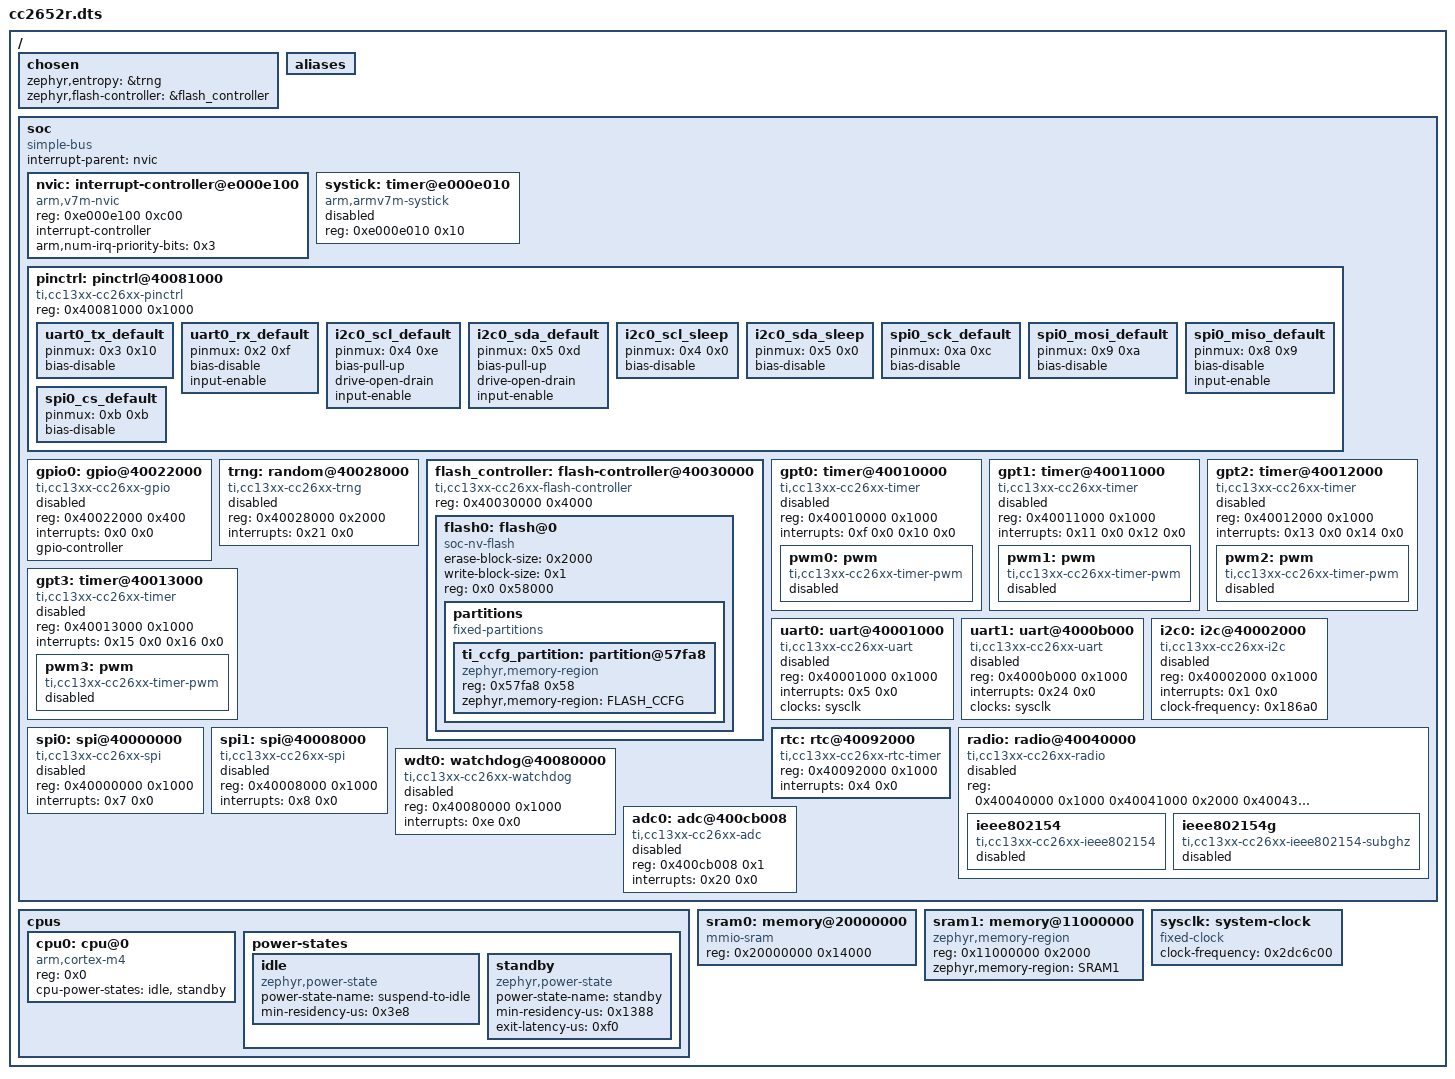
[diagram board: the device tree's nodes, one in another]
/dts-v1/;

/ {
	#address-cells = < 0x1 >;
	#size-cells = < 0x1 >;
	chosen {
		zephyr,entropy = &trng;
		zephyr,flash-controller = &flash_controller;
	};
	aliases {
	};
	soc {
		#address-cells = < 0x1 >;
		#size-cells = < 0x1 >;
		compatible = "simple-bus";
		interrupt-parent = < &nvic >;
		ranges;
		nvic: interrupt-controller@e000e100 {
			#address-cells = < 0x1 >;
			compatible = "arm,v7m-nvic";
			reg = < 0xe000e100 0xc00 >;
			interrupt-controller;
			#interrupt-cells = < 0x2 >;
			arm,num-irq-priority-bits = < 0x3 >;
			phandle = < 0x1 >;
		};
		systick: timer@e000e010 {
			compatible = "arm,armv7m-systick";
			reg = < 0xe000e010 0x10 >;
			status = "disabled";
		};
		pinctrl: pinctrl@40081000 {
			compatible = "ti,cc13xx-cc26xx-pinctrl";
			reg = < 0x40081000 0x1000 >;
			uart0_tx_default: uart0_tx_default {
				pinmux = < 0x3 0x10 >;
				bias-disable;
			};
			uart0_rx_default: uart0_rx_default {
				pinmux = < 0x2 0xf >;
				bias-disable;
				input-enable;
			};
			i2c0_scl_default: i2c0_scl_default {
				pinmux = < 0x4 0xe >;
				bias-pull-up;
				drive-open-drain;
				input-enable;
			};
			i2c0_sda_default: i2c0_sda_default {
				pinmux = < 0x5 0xd >;
				bias-pull-up;
				drive-open-drain;
				input-enable;
			};
			i2c0_scl_sleep: i2c0_scl_sleep {
				pinmux = < 0x4 0x0 >;
				bias-disable;
			};
			i2c0_sda_sleep: i2c0_sda_sleep {
				pinmux = < 0x5 0x0 >;
				bias-disable;
			};
			spi0_sck_default: spi0_sck_default {
				pinmux = < 0xa 0xc >;
				bias-disable;
			};
			spi0_mosi_default: spi0_mosi_default {
				pinmux = < 0x9 0xa >;
				bias-disable;
			};
			spi0_miso_default: spi0_miso_default {
				pinmux = < 0x8 0x9 >;
				bias-disable;
				input-enable;
			};
			spi0_cs_default: spi0_cs_default {
				pinmux = < 0xb 0xb >;
				bias-disable;
			};
		};
		gpio0: gpio@40022000 {
			compatible = "ti,cc13xx-cc26xx-gpio";
			reg = < 0x40022000 0x400 >;
			interrupts = < 0x0 0x0 >;
			status = "disabled";
			gpio-controller;
			#gpio-cells = < 0x2 >;
		};
		trng: random@40028000 {
			compatible = "ti,cc13xx-cc26xx-trng";
			reg = < 0x40028000 0x2000 >;
			interrupts = < 0x21 0x0 >;
			status = "disabled";
		};
		flash_controller: flash-controller@40030000 {
			compatible = "ti,cc13xx-cc26xx-flash-controller";
			reg = < 0x40030000 0x4000 >;
			#address-cells = < 0x1 >;
			#size-cells = < 0x1 >;
			flash0: flash@0 {
				compatible = "soc-nv-flash";
				erase-block-size = < 0x2000 >;
				write-block-size = < 0x1 >;
				reg = < 0x0 0x58000 >;
				partitions {
					compatible = "fixed-partitions";
					#address-cells = < 0x1 >;
					#size-cells = < 0x1 >;
					ti_ccfg_partition: partition@57fa8 {
						compatible = "zephyr,memory-region";
						reg = < 0x57fa8 0x58 >;
						zephyr,memory-region = "FLASH_CCFG";
					};
				};
			};
		};
		gpt0: timer@40010000 {
			compatible = "ti,cc13xx-cc26xx-timer";
			reg = < 0x40010000 0x1000 >;
			interrupts = < 0xf 0x0 0x10 0x0 >;
			interrupt-names = "gpt0a", "gpt0b";
			status = "disabled";
			pwm0: pwm {
				compatible = "ti,cc13xx-cc26xx-timer-pwm";
				#pwm-cells = < 0x1 >;
				status = "disabled";
			};
		};
		gpt1: timer@40011000 {
			compatible = "ti,cc13xx-cc26xx-timer";
			reg = < 0x40011000 0x1000 >;
			interrupts = < 0x11 0x0 0x12 0x0 >;
			interrupt-names = "gpt1a", "gpt1b";
			status = "disabled";
			pwm1: pwm {
				compatible = "ti,cc13xx-cc26xx-timer-pwm";
				#pwm-cells = < 0x1 >;
				status = "disabled";
			};
		};
		gpt2: timer@40012000 {
			compatible = "ti,cc13xx-cc26xx-timer";
			reg = < 0x40012000 0x1000 >;
			interrupts = < 0x13 0x0 0x14 0x0 >;
			interrupt-names = "gpt2a", "gpt2b";
			status = "disabled";
			pwm2: pwm {
				compatible = "ti,cc13xx-cc26xx-timer-pwm";
				#pwm-cells = < 0x1 >;
				status = "disabled";
			};
		};
		gpt3: timer@40013000 {
			compatible = "ti,cc13xx-cc26xx-timer";
			reg = < 0x40013000 0x1000 >;
			interrupts = < 0x15 0x0 0x16 0x0 >;
			interrupt-names = "gpt3a", "gpt3b";
			status = "disabled";
			pwm3: pwm {
				compatible = "ti,cc13xx-cc26xx-timer-pwm";
				#pwm-cells = < 0x1 >;
				status = "disabled";
			};
		};
		uart0: uart@40001000 {
			compatible = "ti,cc13xx-cc26xx-uart";
			reg = < 0x40001000 0x1000 >;
			interrupts = < 0x5 0x0 >;
			clocks = < &sysclk >;
			status = "disabled";
		};
		uart1: uart@4000b000 {
			compatible = "ti,cc13xx-cc26xx-uart";
			reg = < 0x4000b000 0x1000 >;
			interrupts = < 0x24 0x0 >;
			clocks = < &sysclk >;
			status = "disabled";
		};
		i2c0: i2c@40002000 {
			compatible = "ti,cc13xx-cc26xx-i2c";
			#address-cells = < 0x1 >;
			#size-cells = < 0x0 >;
			reg = < 0x40002000 0x1000 >;
			interrupts = < 0x1 0x0 >;
			clock-frequency = < 0x186a0 >;
			status = "disabled";
		};
		spi0: spi@40000000 {
			compatible = "ti,cc13xx-cc26xx-spi";
			#address-cells = < 0x1 >;
			#size-cells = < 0x0 >;
			reg = < 0x40000000 0x1000 >;
			interrupts = < 0x7 0x0 >;
			status = "disabled";
		};
		spi1: spi@40008000 {
			compatible = "ti,cc13xx-cc26xx-spi";
			#address-cells = < 0x1 >;
			#size-cells = < 0x0 >;
			reg = < 0x40008000 0x1000 >;
			interrupts = < 0x8 0x0 >;
			status = "disabled";
		};
		rtc: rtc@40092000 {
			compatible = "ti,cc13xx-cc26xx-rtc-timer";
			reg = < 0x40092000 0x1000 >;
			interrupts = < 0x4 0x0 >;
			status = "okay";
		};
		radio: radio@40040000 {
			compatible = "ti,cc13xx-cc26xx-radio";
			status = "disabled";
			reg = < 0x40040000 0x1000 0x40041000 0x2000 0x40043000 0x1000 0x40044000 0x1000 >;
			reg-names = "RFC_PWR", "RFC_DBELL", "RFC_RAT", "RFC_FSCA";
			ieee802154: ieee802154 {
				compatible = "ti,cc13xx-cc26xx-ieee802154";
				status = "disabled";
			};
			ieee802154g: ieee802154g {
				compatible = "ti,cc13xx-cc26xx-ieee802154-subghz";
				status = "disabled";
			};
		};
		wdt0: watchdog@40080000 {
			compatible = "ti,cc13xx-cc26xx-watchdog";
			reg = < 0x40080000 0x1000 >;
			interrupts = < 0xe 0x0 >;
			status = "disabled";
		};
		adc0: adc@400cb008 {
			compatible = "ti,cc13xx-cc26xx-adc";
			reg = < 0x400cb008 0x1 >;
			interrupts = < 0x20 0x0 >;
			status = "disabled";
			#io-channel-cells = < 0x1 >;
		};
	};
	cpus {
		#address-cells = < 0x1 >;
		#size-cells = < 0x0 >;
		cpu0: cpu@0 {
			device_type = "cpu";
			compatible = "arm,cortex-m4";
			reg = < 0x0 >;
			cpu-power-states = < &idle &standby >;
		};
		power-states {
			idle: idle {
				compatible = "zephyr,power-state";
				power-state-name = "suspend-to-idle";
				min-residency-us = < 0x3e8 >;
				phandle = < 0x3 >;
			};
			standby: standby {
				compatible = "zephyr,power-state";
				power-state-name = "standby";
				min-residency-us = < 0x1388 >;
				exit-latency-us = < 0xf0 >;
				phandle = < 0x4 >;
			};
		};
	};
	sram0: memory@20000000 {
		compatible = "mmio-sram";
		reg = < 0x20000000 0x14000 >;
	};
	sram1: memory@11000000 {
		compatible = "zephyr,memory-region", "mmio-sram";
		reg = < 0x11000000 0x2000 >;
		zephyr,memory-region = "SRAM1";
	};
	sysclk: system-clock {
		compatible = "fixed-clock";
		clock-frequency = < 0x2dc6c00 >;
		#clock-cells = < 0x0 >;
		phandle = < 0x2 >;
	};
};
